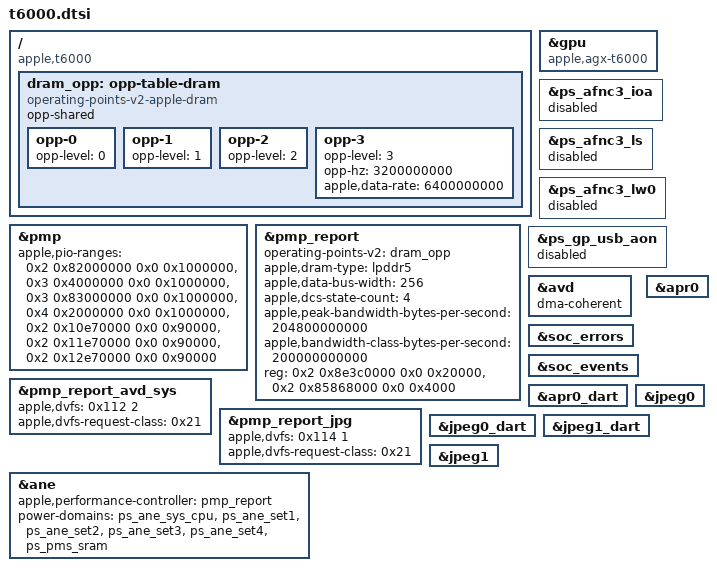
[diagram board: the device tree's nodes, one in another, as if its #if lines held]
// SPDX-License-Identifier: GPL-2.0+ OR MIT
/*
 * Apple T6000 "M1 Pro" SoC
 *
 * Other names: H13J, "Jade Chop"
 *
 * Copyright The Asahi Linux Contributors
 */

/* This chip is just a cut down version of t6001, so include it and disable the missing parts */

#define GPU_REPEAT(x) <x x>
#define APPLE_T6000_SUBSET
#include "t6001.dtsi"

/ {
	compatible = "apple,t6000", "apple,arm-platform";
};

/delete-node/ &pmgr_south;
/delete-node/ &pmp_report_dispext2;
/delete-node/ &pmp_report_dispext3;
/delete-node/ &pmp_report_venc1;
/delete-node/ &pmp_report_msr1;
/delete-node/ &pmp_report_prores;
/delete-node/ &pmp_report_afnc4_ioa;
/delete-node/ &pmp_report_afnc5_ioa;

&pmp {
	apple,pio-ranges = <0x2 0x82000000 0x0 0x1000000>,
		<0x3 0x4000000 0x0 0x1000000>,
		<0x3 0x83000000 0x0 0x1000000>,
		<0x4 0x2000000 0x0 0x1000000>,
		<0x2 0x10e70000 0x0 0x90000>,
		<0x2 0x11e70000 0x0 0x90000>,
		<0x2 0x12e70000 0x0 0x90000>;
};

&gpu {
	compatible = "apple,agx-t6000", "apple,agx-g13x";
};

/*
 * DRAM interface class: width and maximum rate are inferred from topology
 * and the published bandwidth class. Lower-state rates remain unqualified.
 * State IDs below describe firmware DCS states, not PMGR codes.
 */
/ {
	dram_opp: opp-table-dram {
		compatible = "operating-points-v2-apple-dram";
		opp-shared;

		opp-0 {
			opp-level = <0>;
		};

		opp-1 {
			opp-level = <1>;
		};

		opp-2 {
			opp-level = <2>;
		};

		opp-3 {
			opp-level = <3>;
			opp-hz = /bits/ 64 <3200000000>;
			apple,data-rate = /bits/ 64 <6400000000>;
		};
	};
};

&pmp_report {
	operating-points-v2 = <&dram_opp>;
	apple,dram-type = "lpddr5";
	apple,data-bus-width = <256>;
	apple,dcs-state-count = <4>;
	apple,peak-bandwidth-bytes-per-second = /bits/ 64 <204800000000>;
	apple,bandwidth-class-bytes-per-second = /bits/ 64 <200000000000>;
};

&pmp_report {
	reg = <0x2 0x8e3c0000 0x0 0x20000>,
	      <0x2 0x85868000 0x0 0x4000>;
	reg-names = "report", "ane-dvfs";
};

#ifdef APPLE_USE_PMP
/*
 * AVD and the JPEG codecs (one soc-device for both) also send the PMP a
 * performance request while they are powered, in request class 0x21 of
 * their SOC-DEV-DVFS entries: AVD level 2 (VMAX) at 0x112, JPEG level 1
 * (VNOM) at 0x114. The PMP then holds the SoC rail and fabric up for them.
 */
&pmp_report_avd_sys {
	apple,dvfs = <0x112 2>;
	apple,dvfs-request-class = <0x21>;
};

&pmp_report_jpg {
	apple,dvfs = <0x114 1>;
	apple,dvfs-request-class = <0x21>;
};
#endif

&ane {
	apple,performance-controller = <&pmp_report>;
	power-domains = <&ps_ane_sys_cpu>, <&ps_ane_set1>,
		<&ps_ane_set2>, <&ps_ane_set3>, <&ps_ane_set4>, <&ps_pms_sram>;
};

/*
 * T6000 has no power state registers for the AFNC3 fabric controllers or
 * the USB-A AON domain: they are always on without a PMGR switch.
 */
&ps_afnc3_ioa {
	status = "disabled";
};

&ps_afnc3_ls {
	status = "disabled";
};

&ps_afnc3_lw0 {
	status = "disabled";
};

&ps_gp_usb_aon {
	status = "disabled";
};

/* The video decoder is IO-coherent in both directions. */
&avd {
	dma-coherent;
};

#include "t6000-peripherals.dtsi"
#include "t6000-aux-spmi.dtsi"

/* Platform error and event-log interrupt groups (apple_soc_edac). */
&soc_errors {
	status = "okay";
};

&soc_events {
	status = "okay";
};

&apr0_dart {
	status = "okay";
};

&apr0 {
	status = "okay";
};

/* Both JPEG encoders are SoC blocks with no board wiring. */
&jpeg0_dart {
	status = "okay";
};

&jpeg0 {
	status = "okay";
};

&jpeg1_dart {
	status = "okay";
};

&jpeg1 {
	status = "okay";
};
